AUTOSAR XML (schema 4-3-0)
package /HwInput
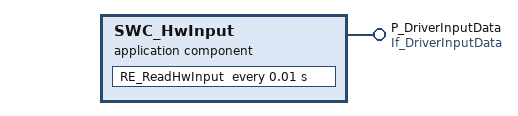
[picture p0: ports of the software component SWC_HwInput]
  application sw component type SWC_HwInput
    provide port P_DriverInputData: provided-com-specs=[BrakeSw, AccelSw, SocLevel, VehicleSpeed, ReadStatus], provided-interface=If_DriverInputData
    behavior InternalBehavior
      timing event TE_RE_ReadHwInput: start-on-event=RE_ReadHwInput, period=0.01
      runnable RE_ReadHwInput: symbol=ReadHwInput_func
        data-send-points:
          5 x access, all with scope=COMMUNICATION-INTER-ECU:
            DSP_RE_ReadHwInput_P_DriverInputData_AccelSw: accessed-variable=P_DriverInputData.AccelSw
            DSP_RE_ReadHwInput_P_DriverInputData_BrakeSw: accessed-variable=P_DriverInputData.BrakeSw
            DSP_RE_ReadHwInput_P_DriverInputData_ReadStatus: accessed-variable=P_DriverInputData.ReadStatus
            DSP_RE_ReadHwInput_P_DriverInputData_SocLevel: accessed-variable=P_DriverInputData.SocLevel
            DSP_RE_ReadHwInput_P_DriverInputData_VehicleSpeed: accessed-variable=P_DriverInputData.VehicleSpeed
  application sw component type SWC_DummyRx
    require port R_DriverInputData: required-interface=If_DriverInputData
    behavior InternalBehavior
